# STM32L4P5 register map
File version: 1.8
CPU: CM4 r0p1, little endian, MPU, FPU, 4 interrupt priority bits
Registers are 32-bit, read-write, reset 0x0 unless marked. A register's access mark holds for its fields unless they carry their own. Offsets are from the block's base; [hi:lo] are bit positions; {n}, {i} and the like mark numbered series; 'fields as' and 'values as' point back to an identical list.

## TIM16 — General purpose timers
Base 0x40014400
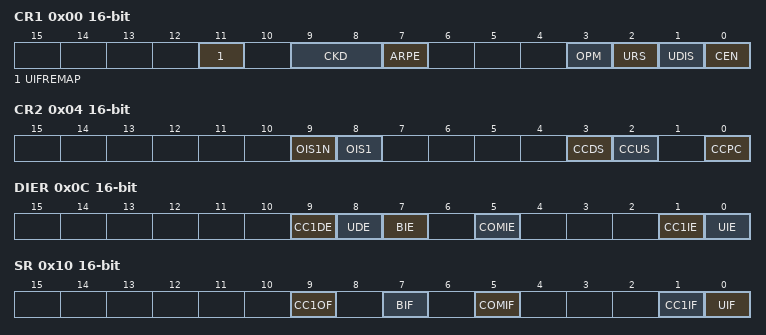
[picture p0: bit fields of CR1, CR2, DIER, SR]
0x00 CR1 16-bit — TIM16 control register 1
  [11] UIFREMAP — UIF status bit remapping
  [9:8] CKD — Clock division This bit-field indicates the division ratio between the timer clock (CK_INT) frequency and the dead-time and sampling clock (t<sub>DTS</sub>)used by the dead-time generators and the digital filters (TIx),
    0=Div1 (t_DTS = t_CK_INT); 1=Div2 (t_DTS = 2 × t_CK_INT); 2=Div4 (t_DTS = 4 × t_CK_INT)
  [7] ARPE — Auto-reload preload enable
    0=Disabled (TIMx_APRR register is not buffered); 1=Enabled (TIMx_APRR register is buffered)
  [3] OPM — One pulse mode
    0=Disabled (Counter is not stopped at update event); 1=Enabled (Counter stops counting at the next update event (clearing the CEN bit))
  [2] URS — Update request source This bit is set and cleared by software to select the UEV event sources. Counter overflow/underflow Setting the UG bit Update generation through the slave mode controller
    0=AnyEvent (Any of counter overflow/underflow, setting UG, or update through slave mode, generates an update interrupt or DMA request); 1=CounterOnly (Only counter overflow/underflow generates an update interrupt or DMA request)
  [1] UDIS — Update disable This bit is set and cleared by software to enable/disable UEV event generation. Counter overflow/underflow Setting the UG bit Update generation through the slave mode controller Buffered registers are then loaded with their preload values.
    0=Enabled (Update event enabled); 1=Disabled (Update event disabled)
  [0] CEN — Counter enable Note: External clock and gated mode can work only if the CEN bit has been previously set by software. However trigger mode can set the CEN bit automatically by hardware.
    0=Disabled (Counter disabled); 1=Enabled (Counter enabled)
0x04 CR2 16-bit — TIM16 control register 2
  [n+8] OIS{n}N (n=1..1) — Output Idle state (OC{n}N output)
    0=Reset (OCxN=0 after a dead-time when MOE=0); 1=Set (OCxN=1 after a dead-time when MOE=0)
  [n+7] OIS{n} (n=1..1) — Output Idle state (OC{n} output)
    0=Reset (OCx=0 (after a dead-time if OCx(N) is implemented) when MOE=0); 1=Set (OCx=1 (after a dead-time if OCx(N) is implemented) when MOE=0)
  [3] CCDS — Capture/compare DMA selection
    0=OnCompare (CCx DMA request sent when CCx event occurs); 1=OnUpdate (CCx DMA request sent when update event occurs)
  [2] CCUS — Capture/compare control update selection Note: This bit acts only on channels that have a complementary output.
    0=Sw (When capture/compare control bits are preloaded (CCPC=1), they are updated by setting the COMG bit only); 1=SwOrEdge (When capture/compare control bits are preloaded (CCPC=1), they are updated by setting the COMG bit or when an rising edge occurs on TRGI)
  [0] CCPC — Capture/compare preloaded control Note: This bit acts only on channels that have a complementary output.
    0=NotPreloaded (CCxE, CCxNE and OCxM bits are not preloaded); 1=Preloaded (CCxE, CCxNE and OCxM bits are preloaded)
0x0C DIER 16-bit — TIM16 DMA/interrupt enable register
  [n+8] CC{n}DE (n=1..1) — Capture/Compare {n} DMA request enable
    0=Disabled (CCx DMA request disabled); 1=Enabled (CCx DMA request enabled)
  [8] UDE — Update DMA request enable
    0=Disabled (Update DMA request disabled); 1=Enabled (Update DMA request enabled)
  [7] BIE — Break interrupt enable
    0=Disabled (Break interrupt disabled); 1=Enabled (Break interrupt enabled)
  [5] COMIE — COM interrupt enable
    0=Disabled (COM interrupt disabled); 1=Enabled (COM interrupt enabled)
  [n] CC{n}IE (n=1..1) — Capture/Compare {n} interrupt enable
    0=Disabled (CCx interrupt disabled); 1=Enabled (CCx interrupt enabled)
  [0] UIE — Update interrupt enable
    0=Disabled (Update interrupt disabled); 1=Enabled (Update interrupt enabled)
0x10 SR 16-bit — TIM16 status register
  [n+8] CC{n}OF (n=1..1) write-0-clears — Capture/Compare {n} overcapture flag
    on read: 0=No overcapture has been detected; 1=Overcapture (The counter value has been captured in TIMx_CCRx register while CCxIF flag was already set) | on write: 0=Clear flag
  [7] BIF write-0-clears — Break interrupt flag This flag is set by hardware as soon as the break input goes active. It can be cleared by software if the break input is not active.
    on read: 0=NoTrigger (No break event occurred); 1=Trigger (An active level has been detected on the break input. An interrupt is generated if BIE=1 in the TIMx_DIER register) | on write: 0=Clear flag
  [5] COMIF write-0-clears — COM interrupt flag
    on read: 0=No COM event occurred; 1=COM (COM interrupt pending) | on write: 0=Clear flag
  [n] CC{n}IF (n=1..1) write-0-clears — Capture/compare {n} interrupt flag
    on read: 0=NoMatch (No campture/compare has been detected); 1=Match (If CC1 is an output: The content of the counter TIMx_CNT matches the content of the TIMx_CCR1 register. If CC1 is an input: The counter value has been captured in TIMx_CCR1 register.) | on write: 0=Clear flag
  [0] UIF write-0-clears — Update interrupt flag This bit is set by hardware on an update event. It is cleared by software. At overflow regarding the repetition counter value (update if repetition counter = 0) and if the UDIS=0 in the TIMx_CR1 register. When CNT is reinitialized by software using the UG bit in TIMx_EGR register, if URS=0 and UDIS=0 in the TIMx_CR1 register.
    on read: 0=NoUpdateOccurred; 1=UpdatePending (Update interrupt pending) | on write: 0=Clear flag
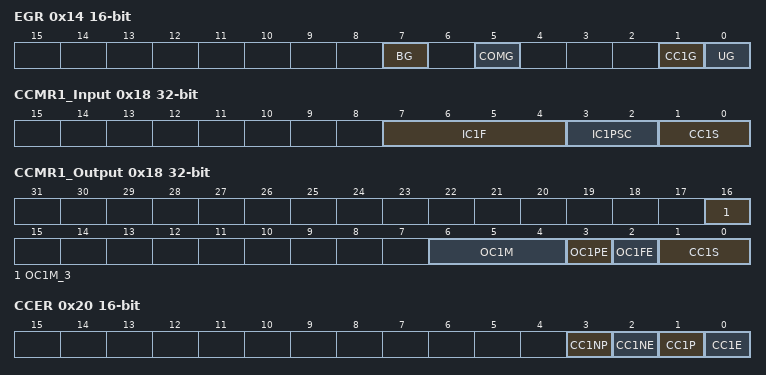
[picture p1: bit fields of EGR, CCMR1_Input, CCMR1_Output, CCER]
0x14 EGR 16-bit wo — TIM16 event generation register
  [7] BG — Break generation This bit is set by software in order to generate an event, it is automatically cleared by hardware.
    1=Trigger (A break event is generated. MOE bit is cleared and BIF flag is set. Related interrupt or DMA transfer can occur if enabled)
  [5] COMG — Capture/Compare control update generation This bit can be set by software, it is automatically cleared by hardware. Note: This bit acts only on channels that have a complementary output.
    1=Trigger (When CCPC bit is set, it allows CCxE, CCxNE and OCxM bits to be updated)
  [n] CC{n}G (n=1..1) — Capture/compare {n} generation
    1=Trigger (If CC1 is an output: CC1IF flag is set, Corresponding interrupt or DMA request is sent if enabled. If CC1 is an input: The current value of the counter is captured in TIMx_CCR1 register.)
  [0] UG — Update generation This bit can be set by software, it is automatically cleared by hardware.
    1=Update (Re-initializes the timer counter and generates an update of the registers.)
0x18 CCMR1_Input — TIM16 capture/compare mode register 1
  [n+6:n+3] IC{n}F (n=1..1) — Input capture {n} filter
    0=No filter, sampling is done at fDTS; 1=FCK_INT_N2 (fSAMPLING=fCK_INT, N=2); 2=FCK_INT_N4 (fSAMPLING=fCK_INT, N=4); 3=FCK_INT_N8 (fSAMPLING=fCK_INT, N=8); 4=FDTS_Div2_N6 (fSAMPLING=fDTS/2, N=6); 5=FDTS_Div2_N8 (fSAMPLING=fDTS/2, N=8); 6=FDTS_Div4_N6 (fSAMPLING=fDTS/4, N=6); 7=FDTS_Div4_N8 (fSAMPLING=fDTS/4, N=8); 8=FDTS_Div8_N6 (fSAMPLING=fDTS/8, N=6); 9=FDTS_Div8_N8 (fSAMPLING=fDTS/8, N=8); 10=FDTS_Div16_N5 (fSAMPLING=fDTS/16, N=5); 11=FDTS_Div16_N6 (fSAMPLING=fDTS/16, N=6); 12=FDTS_Div16_N8 (fSAMPLING=fDTS/16, N=8); 13=FDTS_Div32_N5 (fSAMPLING=fDTS/32, N=5); 14=FDTS_Div32_N6 (fSAMPLING=fDTS/32, N=6); 15=FDTS_Div32_N8 (fSAMPLING=fDTS/32, N=8)
  [n+2:n+1] IC{n}PSC (n=1..1) — Input capture {n} prescaler
    0=No prescaler, capture is done each time an edge is detected on the capture input; 1=TwoEvents (Capture is done once every 2 events); 2=FourEvents (Capture is done once every 4 events); 3=EightEvents (Capture is done once every 8 events)
  [1:0] CC1S — Capture/Compare 1 Selection This bit-field defines the direction of the channel (input/output) as well as the used input. Others: Reserved Note: CC1S bits are writable only when the channel is OFF (CC1E = 0 in TIMx_CCER).
    1=TI1 (CC1 channel is configured as input, IC1 is mapped on TI1)
0x18 CCMR1_Output (alternate view of CCMR1_Input) — TIM16 capture/compare mode register 1
  [n+15] OC{n}M_3 (n=1..1) — Output compare {n} mode, bit 3
  [n+5:n+3] OC{n}M (n=1..1) — Output compare {n} mode
    0=Frozen (The comparison between the output compare register TIMx_CCRy and the counter TIMx_CNT has no effect on the outputs); 1=ActiveOnMatch (Set channel to active level on match. OCyREF signal is forced high when the counter matches the capture/compare register); 2=InactiveOnMatch (Set channel to inactive level on match. OCyREF signal is forced low when the counter matches the capture/compare register); 3=Toggle (OCyREF toggles when TIMx_CNT=TIMx_CCRy); 4=ForceInactive (OCyREF is forced low); 5=ForceActive (OCyREF is forced high); 6=PwmMode1 (In upcounting, channel is active as long as TIMx_CNT<TIMx_CCRy else inactive. In downcounting, channel is inactive as long as TIMx_CNT>TIMx_CCRy else active); 7=PwmMode2 (Inversely to PwmMode1)
  [n+2] OC{n}PE (n=1..1) — Output compare {n} preload enable
    0=Disabled (Preload register on CCRx disabled. New values written to CCRx are taken into account immediately); 1=Enabled (Preload register on CCRx enabled. Preload value is loaded into active register on each update event)
  [n+1] OC{n}FE (n=1..1) — Output compare {n} fast enable
    0=Disabled (Fast output disabled); 1=Enabled (Fast output enabled)
  [n:n-1] CC{n}S (n=1..1) — Capture/Compare {n} selection
    0=Output (CCx channel is configured as output)
0x20 CCER 16-bit — TIM16 capture/compare enable register
  [n+2] CC{n}NP (n=1..1) — Capture/Compare {n} output Polarity
    0=ActiveHigh (OCxN active high); 1=ActiveLow (OCxN active low)
  [n+1] CC{n}NE (n=1..1) — Capture/Compare {n} complementary output enable
    0=Disabled (Complementary output disabled); 1=Enabled (Complementary output enabled)
  [n] CC{n}P (n=1..1) — Capture/Compare {n} output Polarity
    0=RisingEdge (Noninverted/rising edge); 1=FallingEdge (Inverted/falling edge)
  [n-1] CC{n}E (n=1..1) — Capture/Compare {n} output enable
    0=Disabled (Capture disabled); 1=Enabled (Capture enabled)
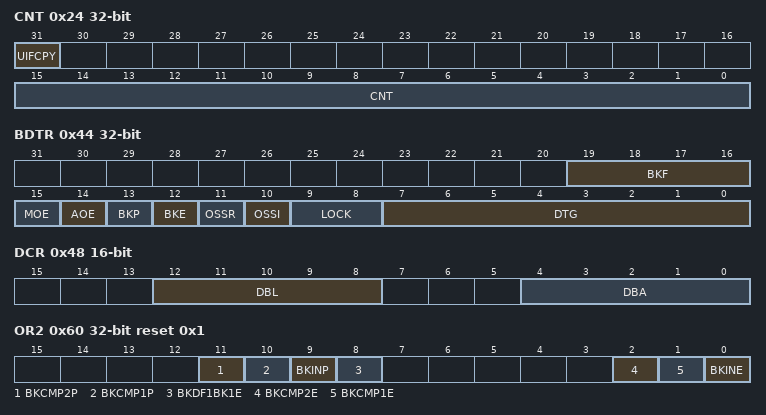
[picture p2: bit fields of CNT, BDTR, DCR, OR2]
0x24 CNT access per field — TIM16 counter
  [31] UIFCPY ro — UIF Copy This bit is a read-only copy of the UIF bit of the TIMx_ISR register. If the UIFREMAP bit in TIMx_CR1 is reset, bit 31 is reserved and read as 0.
  [15:0] CNT rw — Counter value
0x24 CNT16 16-bit (alternate view of CNT) — 16-bit counter register
  [15:0] CNT — counter value
0x28 PSC 16-bit — TIM16 prescaler
  [15:0] PSC — Prescaler value The counter clock frequency (CK_CNT) is equal to f<sub>CK_PSC</sub> / (PSC[15:0] + 1). PSC contains the value to be loaded in the active prescaler register at each update event (including when the counter is cleared through UG bit of TIMx_EGR register or through trigger controller when configured in reset mode ).
0x2C ARR 16-bit reset 0xFFFF — TIM16 auto-reload register
  [15:0] ARR — Auto-reload value ARR is the value to be loaded in the actual auto-reload register. Refer to the Section 26.5.1: Time-base unit on page 862 for more details about ARR update and behavior. The counter is blocked while the auto-reload value is null.
0x30 RCR 16-bit — TIM16 repetition counter register
  [7:0] REP — Repetition counter value These bits allow the user to set-up the update rate of the compare registers (i.e. periodic transfers from preload to active registers) when preload registers are enable, as well as the update interrupt generation rate, if this interrupt is enable. Each time the REP_CNT related downcounter reaches zero, an update event is generated and it restarts counting from REP value. As REP_CNT is reloaded with REP value only at the repetition update event U_RC, any write to the TIMx_RCR register is not taken in account until the next repetition update event. It means in PWM mode (REP+1) corresponds to the number of PWM periods in edge-aligned mode.
{0x32+2i} CCR{i} (i=1..1) 16-bit — capture/compare register
  [15:0] CCR — Capture/Compare value
0x44 BDTR — TIM16 break and dead-time register
  [19:16] BKF — Break filter This bit-field defines the frequency used to sample BRK input and the length of the digital filter applied to BRK. The digital filter is made of an event counter in which N events are needed to validate a transition on the output: This bit cannot be modified when LOCK level 1 has been programmed (LOCK bits in TIMx_BDTR register).
  [15] MOE — Main output enable This bit is cleared asynchronously by hardware as soon as the break input is active. It is set by software or automatically depending on the AOE bit. It is acting only on the channels which are configured in output. See OC/OCN enable description for more details (Section 26.7.8: TIMx capture/compare enable register (TIM16_CCER)(TIMx_CCER)(x = 16 to 17) on page 946).
    0=DisabledIdle (OC/OCN are disabled or forced idle depending on OSSI); 1=Enabled (OC/OCN are enabled if CCxE/CCxNE are set)
  [14] AOE — Automatic output enable Note: This bit can not be modified as long as LOCK level 1 has been programmed (LOCK bits in TIMx_BDTR register).
    0=Manual (MOE can be set only by software); 1=Automatic (MOE can be set by software or automatically at the next update event (if none of the break inputs BRK and BRK2 is active))
  [13] BKP — Break polarity Note: This bit can not be modified as long as LOCK level 1 has been programmed (LOCK bits in TIMx_BDTR register). Note: Any write operation to this bit takes a delay of 1 APB clock cycle to become effective.
    0=ActiveLow (Break input BRKx is active low); 1=ActiveHigh (Break input BRKx is active high)
  [12] BKE — Break enable 1; Break inputs (BRK and CCS clock failure event) enabled Note: This bit cannot be modified when LOCK level 1 has been programmed (LOCK bits in TIMx_BDTR register). Note: Any write operation to this bit takes a delay of 1 APB clock cycle to become effective.
    0=Disabled (Break function x disabled); 1=Enabled (Break function x enabled)
  [11] OSSR — Off-state selection for Run mode This bit is used when MOE=1 on channels that have a complementary output which are configured as outputs. OSSR is not implemented if no complementary output is implemented in the timer. See OC/OCN enable description for more details (Section 26.7.8: TIMx capture/compare enable register (TIM16_CCER)(TIMx_CCER)(x = 16 to 17) on page 946). Note: This bit can not be modified as soon as the LOCK level 2 has been programmed (LOCK bits in TIMx_BDTR register).
    0=HiZ (When inactive, OC/OCN outputs are disabled); 1=IdleLevel (When inactive, OC/OCN outputs are enabled with their inactive level)
  [10] OSSI — Off-state selection for Idle mode This bit is used when MOE=0 on channels configured as outputs. See OC/OCN enable description for more details (Section 26.7.8: TIMx capture/compare enable register (TIM16_CCER)(TIMx_CCER)(x = 16 to 17) on page 946). Note: This bit can not be modified as soon as the LOCK level 2 has been programmed (LOCK bits in TIMx_BDTR register).
    0=HiZ (When inactive, OC/OCN outputs are disabled); 1=IdleLevel (When inactive, OC/OCN outputs are forced to idle level)
  [9:8] LOCK — Lock configuration These bits offer a write protection against software errors. Note: The LOCK bits can be written only once after the reset. Once the TIMx_BDTR register has been written, their content is frozen until the next reset.
    0=Off (No bit is write protected); 1=Level1 (Any bits except MOE, OSSR, OSSI and LOCK in TIMx_BDTR register, OISx and OISxN bits in TIMx_CR2 register can no longer be written); 2=Level2 (LOCK Level 1 + CC Polarity bits (CCxP/CCxNP bits in TIMx_CCER register, as long as the related channel is configured in output through the CCxS bits) as well as OSSR and OSSI bits can no longer be written); 3=Level3 (LOCK Level 2 + CC Control bits (OCxM and OCxPE bits in TIMx_CCMRx registers, as long as the related channel is configured in output through the CCxS bits) can no longer be written)
  [7:0] DTG — Dead-time generator setup
0x48 DCR 16-bit — TIM16 DMA control register
  [12:8] DBL — DMA burst length This 5-bit field defines the length of DMA transfers (the timer recognizes a burst transfer when a read or a write access is done to the TIMx_DMAR address), i.e. the number of transfers. Transfers can be in half-words or in bytes (see example below). ...
  [4:0] DBA — DMA base address This 5-bit field defines the base-address for DMA transfers (when read/write access are done through the TIMx_DMAR address). DBA is defined as an offset starting from the address of the TIMx_CR1 register. Example: ... Example: Let us consider the following transfer: DBL = 7 transfers and DBA = TIMx_CR1. In this case the transfer is done to/from 7 registers starting from the TIMx_CR1 address.
0x4C DMAR 16-bit — TIM16 DMA address for full transfer
  [15:0] DMAB — DMA register for burst accesses A read or write operation to the DMAR register accesses the register located at the address (TIMx_CR1 address) + (DBA + DMA index) x 4 where TIMx_CR1 address is the address of the control register 1, DBA is the DMA base address configured in TIMx_DCR register, DMA index is automatically controlled by the DMA transfer, and ranges from 0 to DBL (DBL configured in TIMx_DCR).
0x50 OR1 — TIM16 option register 1
  [2:0] TI1_RMP — Input capture 1 remap
0x60 OR2 reset 0x1 — TIM16 option register 2
  [11] BKCMP2P — BRK COMP2 input polarity This bit selects the COMP2 input sensitivity. It must be programmed together with the BKP polarity bit. Note: This bit can not be modified as long as LOCK level 1 has been programmed (LOCK bits in TIMx_BDTR register).
  [10] BKCMP1P — BRK COMP1 input polarity This bit selects the COMP1 input sensitivity. It must be programmed together with the BKP polarity bit. Note: This bit can not be modified as long as LOCK level 1 has been programmed (LOCK bits in TIMx_BDTR register).
  [9] BKINP — BRK BKIN input polarity This bit selects the BKIN alternate function input sensitivity. It must be programmed together with the BKP polarity bit. Note: This bit can not be modified as long as LOCK level 1 has been programmed (LOCK bits in TIMx_BDTR register).
  [8] BKDF1BK1E — BRK dfsdm1_break[1] enable This bit enables the dfsdm1_break[1] for the timer s BRK input. dfsdm1_break[1] output is ORed with the other BRK sources. Note: This bit can not be modified as long as LOCK level 1 has been programmed (LOCK bits in TIMx_BDTR register).
  [2] BKCMP2E — BRK COMP2 enable This bit enables the COMP2 for the timer s BRK input. COMP2 output is ORed with the other BRK sources. Note: This bit can not be modified as long as LOCK level 1 has been programmed (LOCK bits in TIMx_BDTR register).
  [1] BKCMP1E — BRK COMP1 enable This bit enables the COMP1 for the timer s BRK input. COMP1 output is ORed with the other BRK sources. Note: This bit can not be modified as long as LOCK level 1 has been programmed (LOCK bits in TIMx_BDTR register).
  [0] BKINE — BRK BKIN input enable This bit enables the BKIN alternate function input for the timer s BRK input. BKIN input is ORed with the other BRK sources. Note: This bit can not be modified as long as LOCK level 1 has been programmed (LOCK bits in TIMx_BDTR register).

## TIM17 — General purpose timers
Base 0x40014800
Registers as TIM16 (with TIM16 read as TIM17); these are added or differ:
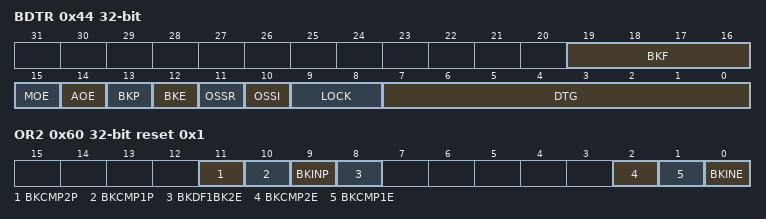
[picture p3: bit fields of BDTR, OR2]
0x44 BDTR — TIM17 break and dead-time register
  fields as TIM16.BDTR
0x50 OR1 — TIM17 option register 1
  [1:0] TI1_RMP — Input capture 1 remap
0x60 OR2 reset 0x1 — TIM17 option register 2
  [11] BKCMP2P — BRK COMP2 input polarity This bit selects the COMP2 input sensitivity. It must be programmed together with the BKP polarity bit. Note: This bit can not be modified as long as LOCK level 1 has been programmed (LOCK bits in TIMx_BDTR register).
  [10] BKCMP1P — BRK COMP1 input polarity This bit selects the COMP1 input sensitivity. It must be programmed together with the BKP polarity bit. Note: This bit can not be modified as long as LOCK level 1 has been programmed (LOCK bits in TIMx_BDTR register).
  [9] BKINP — BRK BKIN input polarity This bit selects the BKIN alternate function input sensitivity. It must be programmed together with the BKP polarity bit. Note: This bit can not be modified as long as LOCK level 1 has been programmed (LOCK bits in TIMx_BDTR register).
  [8] BKDF1BK2E — BRK dfsdm1_break[2] enable This bit enables the dfsdm1_break[2] for the timer s BRK input. dfsdm1_break[2] output is ORed with the other BRK sources. Note: This bit can not be modified as long as LOCK level 1 has been programmed (LOCK bits in TIMx_BDTR register).
  [2] BKCMP2E — BRK COMP2 enable This bit enables the COMP2 for the timer s BRK input. COMP2 output is ORed with the other BRK sources. Note: This bit can not be modified as long as LOCK level 1 has been programmed (LOCK bits in TIMx_BDTR register).
  [1] BKCMP1E — BRK COMP1 enable This bit enables the COMP1 for the timer s BRK input. COMP1 output is ORed with the other BRK sources. Note: This bit can not be modified as long as LOCK level 1 has been programmed (LOCK bits in TIMx_BDTR register).
  [0] BKINE — BRK BKIN input enable This bit enables the BKIN alternate function input for the timer s BRK input. BKIN input is ORed with the other BRK sources. Note: This bit can not be modified as long as LOCK level 1 has been programmed (LOCK bits in TIMx_BDTR register).
